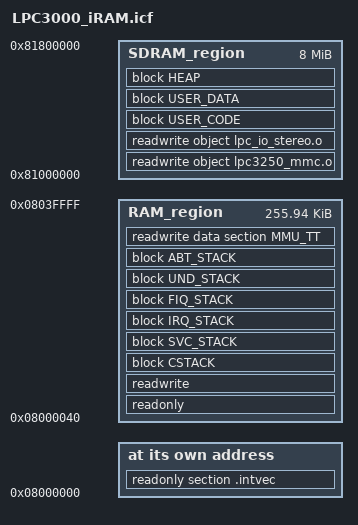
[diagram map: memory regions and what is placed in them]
/*###ICF### Section handled by ICF editor, don't touch! ****/
/*-Editor annotation file-*/
/* IcfEditorFile="$TOOLKIT_DIR$\config\ide\IcfEditor\a_v1_0.xml" */
/*-Specials-*/
define symbol __ICFEDIT_intvec_start__ = 0x08000000;
/*-Memory Regions-*/
define symbol __ICFEDIT_region_ROM_start__   = 0x00;
define symbol __ICFEDIT_region_ROM_end__     = 0x00;
define symbol __ICFEDIT_region_RAM_start__   = 0x08000040;
define symbol __ICFEDIT_region_RAM_end__     = 0x0803FFFF;
define symbol __ICFEDIT_region_SDRAM_start__   = 0x81000000;
define symbol __ICFEDIT_region_SDRAM_end__     = 0x81800000;

/*-Sizes-*/
define symbol __ICFEDIT_size_cstack__   = 0x1F40;
define symbol __ICFEDIT_size_svcstack__ = 0x40;
define symbol __ICFEDIT_size_irqstack__ = 0x500;
define symbol __ICFEDIT_size_fiqstack__ = 0x0;
define symbol __ICFEDIT_size_undstack__ = 0x0;
define symbol __ICFEDIT_size_abtstack__ = 0x0;
define symbol __ICFEDIT_size_heap__     = 0x400000;
/**** End of ICF editor section. ###ICF###*/

define memory mem with size = 4G;
define region RAM_region   = mem:[from __ICFEDIT_region_RAM_start__   to __ICFEDIT_region_RAM_end__];
define region SDRAM_region   = mem:[from __ICFEDIT_region_SDRAM_start__   to __ICFEDIT_region_SDRAM_end__];

define block CSTACK    with alignment = 8, size = __ICFEDIT_size_cstack__   { };
define block SVC_STACK with alignment = 8, size = __ICFEDIT_size_svcstack__ { };
define block IRQ_STACK with alignment = 8, size = __ICFEDIT_size_irqstack__ { };
define block FIQ_STACK with alignment = 8, size = __ICFEDIT_size_fiqstack__ { };
define block UND_STACK with alignment = 8, size = __ICFEDIT_size_undstack__ { };
define block ABT_STACK with alignment = 8, size = __ICFEDIT_size_abtstack__ { };
define block HEAP      with alignment = 8, size = __ICFEDIT_size_heap__     { };

define block USER_DATA with fixed order
{
readwrite object AAFilter.o,
readwrite object BPMDetect.o,
readwrite object FIFOSampleBuffer.o,
readwrite object FIRFilter.o,
readwrite object InterpolateCubic.o,
readwrite object InterpolateLinear.o,
readwrite object InterpolateShannon.o,
readwrite object mmx_optimized.o,
readwrite object PeakFinder.o,
readwrite object RateTransposer.o,
readwrite object RunParameters.o,
readwrite object SoundTouch.o,
readwrite object sse_optimized.o,
readwrite object TDStretch.o,
readwrite object WavFile.o
};


define block USER_CODE with fixed order
{
readonly object AAFilter.o,
readonly object BPMDetect.o,
readonly object FIFOSampleBuffer.o,
readonly object FIRFilter.o,
readonly object InterpolateCubic.o,
readonly object InterpolateLinear.o,
readonly object InterpolateShannon.o,
readonly object mmx_optimized.o,
readonly object PeakFinder.o,
readonly object RateTransposer.o,
readonly object RunParameters.o,
readonly object SoundTouch.o,
readonly object sse_optimized.o,
readonly object TDStretch.o,
readonly object WavFile.o
};


initialize by copy with packing = zeros { readwrite};


/*initialize by copy { readonly, readwrite };*/
do not initialize  { section .noinit };
do not initialize  { section MMU_TT };

place at address mem:__ICFEDIT_intvec_start__ { readonly section .intvec };

place in RAM_region   { readonly };

place in RAM_region   { readwrite,
                        block CSTACK, block SVC_STACK, block IRQ_STACK, block FIQ_STACK,
                        block UND_STACK, block ABT_STACK, 
                        readwrite data section MMU_TT};

place in SDRAM_region   {readwrite object lpc3250_mmc.o, readwrite object lpc_io_stereo.o,
			block USER_CODE, block USER_DATA};

place in SDRAM_region   {block HEAP};
